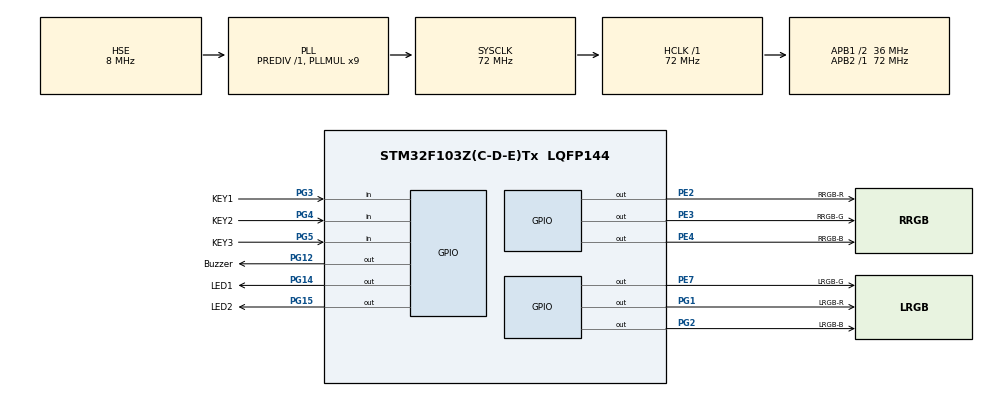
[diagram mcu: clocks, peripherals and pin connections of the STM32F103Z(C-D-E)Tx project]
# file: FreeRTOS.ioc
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FREERTOS.Tasks01=myTask_RGB,0,128,StartTask_RGB,Default,NULL,Dynamic,NULL,NULL;myTask_Beep,-3,128,StartTask_Beep,Default,NULL,Dynamic,NULL,NULL;myTask_KEY,-3,128,StartTask_KEY,Default,NULL,Dynamic,NULL,NULL;myTask_LED,-3,128,StartTask_LED,Default,NULL,Dynamic,NULL,NULL
Mcu.Family=STM32F1
Mcu.Name=STM32F103Z(C-D-E)Tx
Mcu.Package=LQFP144
NVIC.PriorityGroup=NVIC_PRIORITYGROUP_4
NVIC.TIM1_UP_IRQn=true\:15\:0\:false\:false\:true\:false\:false\:true\:true
NVIC.TimeBase=TIM1_UP_IRQn
NVIC.TimeBaseIP=TIM1
OSC_IN.Mode=HSE-External-Oscillator
OSC_IN.Signal=RCC_OSC_IN
OSC_OUT.Mode=HSE-External-Oscillator
OSC_OUT.Signal=RCC_OSC_OUT
PA13.Mode=Serial_Wire
PA13.Signal=SYS_JTMS-SWDIO
PA14.Mode=Serial_Wire
PA14.Signal=SYS_JTCK-SWCLK
PE2.GPIO_Label=RRGB-R
PE2.Signal=GPIO_Output
PE3.GPIO_Label=RRGB-G
PE3.Signal=GPIO_Output
PE4.GPIO_Label=RRGB-B
PE4.Signal=GPIO_Output
PE7.GPIO_Label=LRGB-G
PE7.Signal=GPIO_Output
PG1.GPIO_Label=LRGB-R
PG1.Signal=GPIO_Output
PG12.GPIO_Label=Buzzer
PG12.Signal=GPIO_Output
PG14.GPIO_Label=LED1
PG14.Signal=GPIO_Output
PG15.GPIO_Label=LED2
PG15.Signal=GPIO_Output
PG2.GPIO_Label=LRGB-B
PG2.Signal=GPIO_Output
PG3.GPIO_Label=KEY1
PG3.Signal=GPIO_Input
PG4.GPIO_Label=KEY2
PG4.Signal=GPIO_Input
PG5.GPIO_Label=KEY3
PG5.Signal=GPIO_Input
ProjectManager.HeapSize=0x200
ProjectManager.StackSize=0x400
ProjectManager.TargetToolchain=STM32CubeIDE
RCC.AHBFreq_Value=72000000
RCC.APB1CLKDivider=RCC_HCLK_DIV2
RCC.APB1Freq_Value=36000000
RCC.APB1TimFreq_Value=72000000
RCC.APB2Freq_Value=72000000
RCC.APB2TimFreq_Value=72000000
RCC.HCLKFreq_Value=72000000
RCC.PLLMUL=RCC_PLL_MUL9
RCC.PLLSourceVirtual=RCC_PLLSOURCE_HSE
RCC.SYSCLKFreq_VALUE=72000000
RCC.SYSCLKSource=RCC_SYSCLKSOURCE_PLLCLK
RCC.USBFreq_Value=72000000
VP_FREERTOS_VS_CMSIS_V1.Mode=CMSIS_V1
VP_SYS_VS_tim1.Mode=TIM1
board=custom

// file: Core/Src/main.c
/* USER CODE BEGIN Header */
/**
  ******************************************************************************
  * @file           : main.c
  * @brief          : Main program body
  ******************************************************************************
  * @attention
  *
  * Copyright (c) 2023 STMicroelectronics.
  * All rights reserved.
  *
  * This software is licensed under terms that can be found in the LICENSE file
  * in the root directory of this software component.
  * If no LICENSE file comes with this software, it is provided AS-IS.
  *
  ******************************************************************************
  */
/* USER CODE END Header */
#include "main.h"
#include "cmsis_os.h"
#include "gpio.h"

void SystemClock_Config(void);
void MX_FREERTOS_Init(void);

int main(void)
{

  /* MCU Configuration--------------------------------------------------------*/

  /* Reset of all peripherals, Initializes the Flash interface and the Systick. */
  HAL_Init();

  /* Configure the system clock */
  SystemClock_Config();

  /* Initialize all configured peripherals */
  MX_GPIO_Init();

  /* Call init function for freertos objects (in freertos.c) */
  MX_FREERTOS_Init();

  /* Start scheduler */
  osKernelStart();

  /* We should never get here as control is now taken by the scheduler */
  /* Infinite loop */
  while (1)
  {

  }
}

void SystemClock_Config(void)
{
  RCC_OscInitTypeDef RCC_OscInitStruct = {0};
  RCC_ClkInitTypeDef RCC_ClkInitStruct = {0};

  /** Initializes the RCC Oscillators according to the specified parameters
  * in the RCC_OscInitTypeDef structure.
  */
  RCC_OscInitStruct.OscillatorType = RCC_OSCILLATORTYPE_HSE;
  RCC_OscInitStruct.HSEState = RCC_HSE_ON;
  RCC_OscInitStruct.HSEPredivValue = RCC_HSE_PREDIV_DIV1;
  RCC_OscInitStruct.HSIState = RCC_HSI_ON;
  RCC_OscInitStruct.PLL.PLLState = RCC_PLL_ON;
  RCC_OscInitStruct.PLL.PLLSource = RCC_PLLSOURCE_HSE;
  RCC_OscInitStruct.PLL.PLLMUL = RCC_PLL_MUL9;
  if (HAL_RCC_OscConfig(&RCC_OscInitStruct) != HAL_OK)
  {
    Error_Handler();
  }

  /** Initializes the CPU, AHB and APB buses clocks
  */
  RCC_ClkInitStruct.ClockType = RCC_CLOCKTYPE_HCLK|RCC_CLOCKTYPE_SYSCLK
                              |RCC_CLOCKTYPE_PCLK1|RCC_CLOCKTYPE_PCLK2;
  RCC_ClkInitStruct.SYSCLKSource = RCC_SYSCLKSOURCE_PLLCLK;
  RCC_ClkInitStruct.AHBCLKDivider = RCC_SYSCLK_DIV1;
  RCC_ClkInitStruct.APB1CLKDivider = RCC_HCLK_DIV2;
  RCC_ClkInitStruct.APB2CLKDivider = RCC_HCLK_DIV1;

  if (HAL_RCC_ClockConfig(&RCC_ClkInitStruct, FLASH_LATENCY_2) != HAL_OK)
  {
    Error_Handler();
  }
}

void HAL_TIM_PeriodElapsedCallback(TIM_HandleTypeDef *htim)
{
  if (htim->Instance == TIM1) {
    HAL_IncTick();
  }
}

void Error_Handler(void)
{
  __disable_irq();
  while (1)
  {
  }
}

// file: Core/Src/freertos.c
/* USER CODE BEGIN Header */
/**
  ******************************************************************************
  * File Name          : freertos.c
  * Description        : Code for freertos applications
  ******************************************************************************
  * @attention
  *
  * Copyright (c) 2023 STMicroelectronics.
  * All rights reserved.
  *
  * This software is licensed under terms that can be found in the LICENSE file
  * in the root directory of this software component.
  * If no LICENSE file comes with this software, it is provided AS-IS.
  *
  ******************************************************************************
  */
/* USER CODE END Header */

#include "FreeRTOS.h"
#include "task.h"
#include "main.h"
#include "cmsis_os.h"

/* USER CODE BEGIN Includes */
#include "bsp.h"
/* USER CODE END Includes */

osThreadId myTask_RGBHandle;
osThreadId myTask_BeepHandle;
osThreadId myTask_KEYHandle;
osThreadId myTask_LEDHandle;

void StartTask_RGB(void const * argument);
void StartTask_Beep(void const * argument);
void StartTask_KEY(void const * argument);
void StartTask_LED(void const * argument);

void MX_FREERTOS_Init(void); /* (MISRA C 2004 rule 8.1) */

/* GetIdleTaskMemory prototype (linked to static allocation support) */
void vApplicationGetIdleTaskMemory( StaticTask_t **ppxIdleTaskTCBBuffer, StackType_t **ppxIdleTaskStackBuffer, uint32_t *pulIdleTaskStackSize );

/* USER CODE BEGIN GET_IDLE_TASK_MEMORY */
static StaticTask_t xIdleTaskTCBBuffer;
static StackType_t xIdleStack[configMINIMAL_STACK_SIZE];

void vApplicationGetIdleTaskMemory( StaticTask_t **ppxIdleTaskTCBBuffer, StackType_t **ppxIdleTaskStackBuffer, uint32_t *pulIdleTaskStackSize )
{
  *ppxIdleTaskTCBBuffer = &xIdleTaskTCBBuffer;
  *ppxIdleTaskStackBuffer = &xIdleStack[0];
  *pulIdleTaskStackSize = configMINIMAL_STACK_SIZE;
  /* place for user code */
}
/* USER CODE END GET_IDLE_TASK_MEMORY */

void MX_FREERTOS_Init(void) {

  /* Create the thread(s) */
  /* definition and creation of myTask_RGB */
  osThreadDef(myTask_RGB, StartTask_RGB, osPriorityNormal, 0, 128);
  myTask_RGBHandle = osThreadCreate(osThread(myTask_RGB), NULL);

  /* definition and creation of myTask_Beep */
  osThreadDef(myTask_Beep, StartTask_Beep, osPriorityIdle, 0, 128);
  myTask_BeepHandle = osThreadCreate(osThread(myTask_Beep), NULL);

  /* definition and creation of myTask_KEY */
  osThreadDef(myTask_KEY, StartTask_KEY, osPriorityIdle, 0, 128);
  myTask_KEYHandle = osThreadCreate(osThread(myTask_KEY), NULL);

  /* definition and creation of myTask_LED */
  osThreadDef(myTask_LED, StartTask_LED, osPriorityIdle, 0, 128);
  myTask_LEDHandle = osThreadCreate(osThread(myTask_LED), NULL);

}

void StartTask_RGB(void const * argument)
{
  /* USER CODE BEGIN StartTask_RGB */
	/* Infinite loop */
	Task_Entity_RGB();
  /* USER CODE END StartTask_RGB */
}

void StartTask_Beep(void const * argument)
{
  /* USER CODE BEGIN StartTask_Beep */
	/* Infinite loop */
	Task_Entity_BEEP();
  /* USER CODE END StartTask_Beep */
}

void StartTask_KEY(void const * argument)
{
  /* USER CODE BEGIN StartTask_KEY */
	/* Infinite loop */
	Task_Entity_KEY();
  /* USER CODE END StartTask_KEY */
}

void StartTask_LED(void const * argument)
{
  /* USER CODE BEGIN StartTask_LED */
	/* Infinite loop */
	Task_Entity_LED();
  /* USER CODE END StartTask_LED */
}
